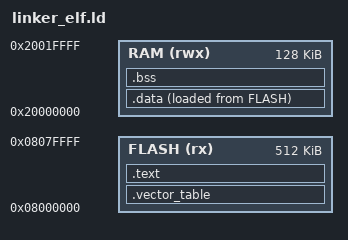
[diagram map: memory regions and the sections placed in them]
/* linker_elf.ld — Linker script with .data init support for ELF loader test */
MEMORY
{
    FLASH (rx)  : ORIGIN = 0x08000000, LENGTH = 512K
    RAM   (rwx) : ORIGIN = 0x20000000, LENGTH = 128K
}

ENTRY(reset_handler)

SECTIONS
{
    .vector_table : { KEEP(*(.vector_table)) } > FLASH
    .text : { *(.text*) *(.rodata*) } > FLASH

    _data_flash = LOADADDR(.data);
    .data : {
        _data_start = .;
        *(.data*)
        _data_end = .;
    } > RAM AT > FLASH

    .bss : {
        _bss_start = .;
        *(.bss*)
        *(COMMON)
        _bss_end = .;
    } > RAM

    _stack_top = ORIGIN(RAM) + LENGTH(RAM);
}
